# TLSR8278 register map
File version: 0.1
Registers are 8-bit, access not given, no defined reset value unless marked. A register's access mark holds for its fields unless they carry their own. Offsets are from the block's base; [hi:lo] are bit positions; {n}, {i} and the like mark numbered series.

## FIFO — Auto-generated from section 'fifo'
Base 0x00800800
{0x0+0x100*i} FIFO{i}_DATA 32-bit (i=0..2) — Auto-generated from fifo{i}_data

## DFIFO — Auto-generated from section 'dfifo'
Base 0x00800B00
{0x0+4i} DFIFO{i}_ADDR 16-bit (i=0..2) — Auto-generated from dfifo{i}_addr
{0x2+4i} DFIFO{i}_SIZE (i=0..2) — Auto-generated from dfifo{i}_size
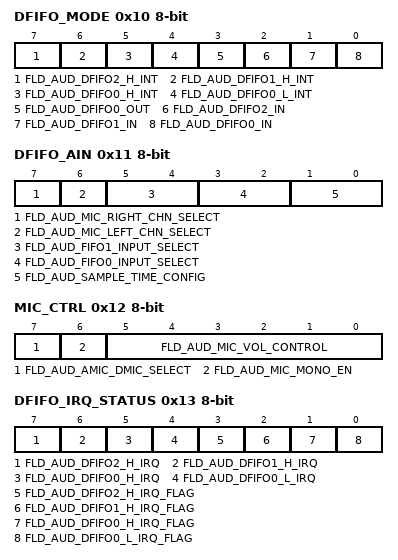
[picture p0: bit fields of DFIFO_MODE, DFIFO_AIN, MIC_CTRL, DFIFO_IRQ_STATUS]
0x10 DFIFO_MODE — Auto-generated from dfifo_mode
  [7] FLD_AUD_DFIFO2_H_INT, [6] FLD_AUD_DFIFO1_H_INT, [5] FLD_AUD_DFIFO0_H_INT, [4] FLD_AUD_DFIFO0_L_INT, [3] FLD_AUD_DFIFO0_OUT, [2] FLD_AUD_DFIFO2_IN, [1] FLD_AUD_DFIFO1_IN, [0] FLD_AUD_DFIFO0_IN
0x11 DFIFO_AIN — Auto-generated from dfifo_ain
  [7] FLD_AUD_MIC_RIGHT_CHN_SELECT, [6] FLD_AUD_MIC_LEFT_CHN_SELECT, [5:4] FLD_AUD_FIFO1_INPUT_SELECT, [3:2] FLD_AUD_FIFO0_INPUT_SELECT, [1:0] FLD_AUD_SAMPLE_TIME_CONFIG
0x12 MIC_CTRL — Auto-generated from mic_ctrl
  [7] FLD_AUD_AMIC_DMIC_SELECT, [6] FLD_AUD_MIC_MONO_EN, [5:0] FLD_AUD_MIC_VOL_CONTROL
0x13 DFIFO_IRQ_STATUS — Auto-generated from dfifo_irq_status
  [7] FLD_AUD_DFIFO2_H_IRQ, [6] FLD_AUD_DFIFO1_H_IRQ, [5] FLD_AUD_DFIFO0_H_IRQ, [4] FLD_AUD_DFIFO0_L_IRQ, [3] FLD_AUD_DFIFO2_H_IRQ_FLAG, [2] FLD_AUD_DFIFO1_H_IRQ_FLAG, [1] FLD_AUD_DFIFO0_H_IRQ_FLAG, [0] FLD_AUD_DFIFO0_L_IRQ_FLAG
{0x14+4i} DFIFO{i}_RPTR 16-bit (i=0..2) — Auto-generated from dfifo{i}_rptr
{0x16+4i} DFIFO{i}_WPTR 16-bit (i=0..2) — Auto-generated from dfifo{i}_wptr
{0x20+4i} DFIFO{i}_NUM 16-bit (i=0..2) — Auto-generated from dfifo{i}_num
0x2C DFIFO_MANUAL_MODE — Auto-generated from dfifo_manual_mode
  [0] FLD_DFIFO_MANUAL_MODE_EN
0x30 DFIFO0_MAN_DAT 32-bit — Auto-generated from dfifo0_man_dat
0x80 SET_FILTER_PARA — Auto-generated from set_filter_para
0x8A DFIFO_DEC_RATIO — Auto-generated from dfifo_dec_ratio
0x8B CODEC_DEC_EN — Auto-generated from codec_dec_en
  [0] FLD_AUD_CODEC_DEC_EN

## DMA — Auto-generated from section 'dma'
Base 0x00800C00
{0x0+4i} DMA{i}_ADDR 16-bit (i=0..5) — Auto-generated from dma{i}_addr
{0x2+4i} DMA{i}_SIZE (i=0..5) — Auto-generated from dma{i}_size
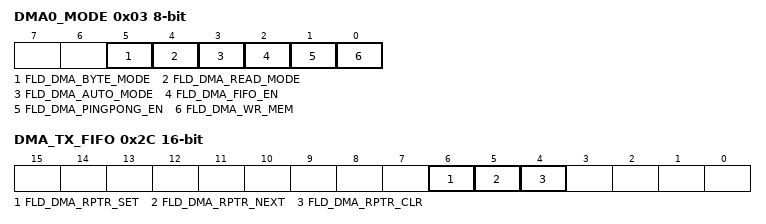
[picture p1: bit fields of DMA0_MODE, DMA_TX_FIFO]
0x03 DMA0_MODE — Auto-generated from dma0_mode
  [5] FLD_DMA_BYTE_MODE, [4] FLD_DMA_READ_MODE, [3] FLD_DMA_AUTO_MODE, [2] FLD_DMA_FIFO_EN, [1] FLD_DMA_PINGPONG_EN, [0] FLD_DMA_WR_MEM
{0x3+4i} DMA{i}_MODE (i=1..5) — Auto-generated from dma{i}_mode
0x18 DMA7_ADDR 16-bit — Auto-generated from dma7_addr
0x1A DMA7_SIZE — Auto-generated from dma7_size
0x1B DMA7_MODE — Auto-generated from dma7_mode
0x1C DMA_T_ADDR 16-bit — Auto-generated from dma_t_addr
0x1E DMA_T_SIZE — Auto-generated from dma_t_size
0x20 DMA_CHN_EN — Auto-generated from dma_chn_en
0x21 DMA_CHN_IRQ_MSK — Auto-generated from dma_chn_irq_msk
0x24 DMA_TX_RDY0 — Auto-generated from dma_tx_rdy0
0x25 DMA_TX_RDY1 — Auto-generated from dma_tx_rdy1
0x26 DMA_RX_RDY0 — Auto-generated from dma_rx_rdy0
0x27 DMA_RX_RDY1 — Auto-generated from dma_rx_rdy1
  [7] FLD_DMA_CHN7, [7] FLD_DMA_CHN_PWM, [n] FLD_DMA_CHN{n} (n=0..5), [5] FLD_DMA_CHN_AES_IN, [4] FLD_DMA_CHN_AES_OUT, [3] FLD_DMA_CHN_RF_TX, [2] FLD_DMA_CHN_RF_RX, [1] FLD_DMA_CHN_UART_TX, [0] FLD_DMA_CHN_UART_RX
0x28 DMA_RX_RPTR — Auto-generated from dma_rx_rptr
0x29 DMA_RX_WPTR — Auto-generated from dma_rx_wptr
0x2A DMA_TX_RPTR — Auto-generated from dma_tx_rptr
0x2B DMA_TX_WPTR — Auto-generated from dma_tx_wptr
0x2C DMA_TX_FIFO 16-bit — Auto-generated from dma_tx_fifo
  [6] FLD_DMA_RPTR_SET, [5] FLD_DMA_RPTR_NEXT, [4] FLD_DMA_RPTR_CLR
{0x40+i} DMA{i}_ADDRHI (i=0..5) — Auto-generated from dma{i}_addrhi
0x46 DMA_TA_ADDRHI — Auto-generated from dma_ta_addrhi
0x47 DMA_A3_ADDRHI — Auto-generated from dma_a3_addrhi
0x48 DMA7_ADDRHI — Auto-generated from dma7_addrhi

## LINKLAYER — Auto-generated from section 'linklayer'
Base 0x00800F02
0x00 RF_LL_CTRL_0 — Auto-generated from rf_ll_ctrl_0
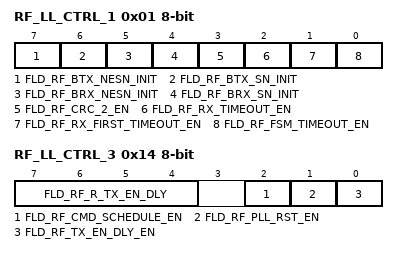
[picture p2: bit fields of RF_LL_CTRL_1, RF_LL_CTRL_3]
0x01 RF_LL_CTRL_1 — Auto-generated from rf_ll_ctrl_1
  [7] FLD_RF_BTX_NESN_INIT, [6] FLD_RF_BTX_SN_INIT, [5] FLD_RF_BRX_NESN_INIT, [4] FLD_RF_BRX_SN_INIT, [3] FLD_RF_CRC_2_EN, [2] FLD_RF_RX_TIMEOUT_EN, [1] FLD_RF_RX_FIRST_TIMEOUT_EN, [0] FLD_RF_FSM_TIMEOUT_EN
0x08 RF_RX_TIMEOUT 16-bit — Auto-generated from rf_rx_timeout
0x13 RF_LL_CTRL_2 — Auto-generated from rf_ll_ctrl_2
0x14 RF_LL_CTRL_3 — Auto-generated from rf_ll_ctrl_3
  [7:4] FLD_RF_R_TX_EN_DLY, [2] FLD_RF_CMD_SCHEDULE_EN, [1] FLD_RF_PLL_RST_EN, [0] FLD_RF_TX_EN_DLY_EN
0x1A RF_IRQ_MASK 16-bit — Auto-generated from rf_irq_mask
0x1E RF_IRQ_STATUS 16-bit — Auto-generated from rf_irq_status
0x2A RF_FSM_TIMEOUT 32-bit — Auto-generated from rf_fsm_timeout
  [12] FLD_RF_IRQ_STX_TIMEOUT, [11] FLD_RF_IRQ_INVALID_PID, [10] FLD_RF_IRQ_FIRST_TIMEOUT, [9] FLD_RF_IRQ_RX_DR, [8] FLD_RF_IRQ_TX_DS, [7] FLD_CLK_48M_TO_CAL_DIG_MAN_EN, [7] FLD_RF_IRQ_RETRY_HIT, [7] FLD_XO_CAP_OFF_ANA, [6] FLD_AUTO_PD_OTP, [6] FLD_CLK_24M_TO_SAR_EN, [6] FLD_RF_IRQ_FSM_TIMEOUT, [7:6] FLD_RF_RX_MI_INTEGER_1, [7:6] FLD_RF_TX_MI_INTEGER_1, [6] FLD_XO_MODE_ANA, [5] FLD_AUTO_PD_XTAL_QUICK_RST, [5] FLD_CLK_48M_TO_DIG_EN, [5] FLD_RF_IRQ_CMD_DONE, [4] FLD_AUTO_PD_MISC, [4] FLD_CLK_48M_TO_RX_EN, [4] FLD_PLL_BG_POWER_DOWN, [7:4] FLD_RF_HPMC_EXP_DIFF_COUNT_L, [4] FLD_RF_IRQ_RX_CRC_2, [4] FLD_RST_MDEC, [3] FLD_AUTO_PD_LC_COMP, [3] FLD_DCCC_DOUBLER_POWER_DOWN, [3] FLD_SELE_PD0, [2] FLD_AUTO_PD_XTAL_24M, [2] FLD_RF_IRQ_RX_TIMEOUT, [2] FLD_SELE_PC4, [1] FLD_AUTO_PD_PL_DCDC, [1] FLD_AUTO_PD_XTAL_32K, [1] FLD_RF_IRQ_TX, [3:1] FLD_RF_VCO_TRIM_KVM, [1] FLD_SELE_PB7, [0] FLD_AUTO_PD_PL_ALL, [0] FLD_AUTO_PD_RC_32K, [3:0] FLD_CLS_MATCH_ADDR, [4:0] FLD_CLS_MDEC, [0] FLD_RF_BLE_MODE_TX, [0] FLD_RF_IRQ_RX, [5:0] FLD_RF_RX_MI_FRACTION, [0] FLD_RF_RX_MI_INTEGER_2, [5:0] FLD_RF_TX_MI_FRACTION, [0] FLD_RF_TX_MI_INTEGER_2, [0] FLD_SELE_PA0, [5:0] FLD_XO_CDAC_ANA
